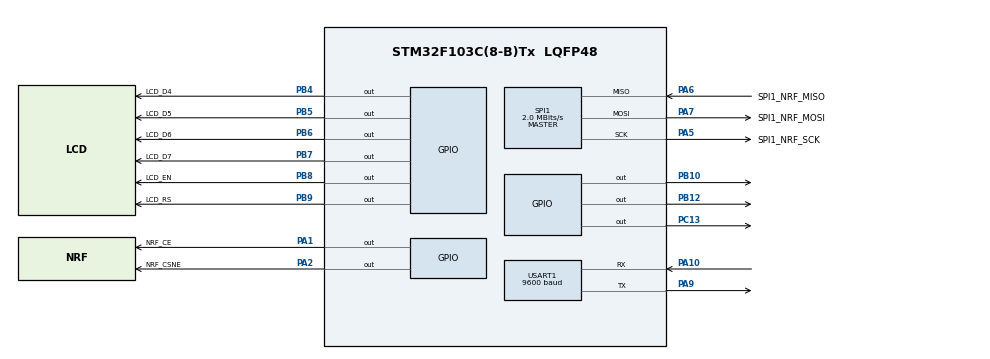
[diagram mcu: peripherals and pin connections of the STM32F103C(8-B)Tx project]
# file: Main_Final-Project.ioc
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Mcu.Family=STM32F1
Mcu.Name=STM32F103C(8-B)Tx
Mcu.Package=LQFP48
NVIC.PriorityGroup=NVIC_PRIORITYGROUP_4
PA1.GPIO_Label=NRF_CE
PA1.Signal=GPIO_Output
PA10.Mode=Asynchronous
PA10.Signal=USART1_RX
PA13.Mode=Serial_Wire
PA13.Signal=SYS_JTMS-SWDIO
PA14.Mode=Serial_Wire
PA14.Signal=SYS_JTCK-SWCLK
PA2.GPIO_Label=NRF_CSNE
PA2.Signal=GPIO_Output
PA5.GPIO_Label=SPI1_NRF_SCK
PA5.Mode=Full_Duplex_Master
PA5.Signal=SPI1_SCK
PA6.GPIO_Label=SPI1_NRF_MISO
PA6.Mode=Full_Duplex_Master
PA6.Signal=SPI1_MISO
PA7.GPIO_Label=SPI1_NRF_MOSI
PA7.Mode=Full_Duplex_Master
PA7.Signal=SPI1_MOSI
PA9.Mode=Asynchronous
PA9.Signal=USART1_TX
PB10.Signal=GPIO_Output
PB12.GPIO_Speed=GPIO_SPEED_FREQ_MEDIUM
PB12.PinState=GPIO_PIN_RESET
PB12.Signal=GPIO_Output
PB4.GPIO_Label=LCD_D4
PB4.Signal=GPIO_Output
PB5.GPIO_Label=LCD_D5
PB5.Signal=GPIO_Output
PB6.GPIO_Label=LCD_D6
PB6.Signal=GPIO_Output
PB7.GPIO_Label=LCD_D7
PB7.Signal=GPIO_Output
PB8.GPIO_Label=LCD_EN
PB8.Signal=GPIO_Output
PB9.GPIO_Label=LCD_RS
PB9.Signal=GPIO_Output
PC13-TAMPER-RTC.Signal=GPIO_Output
PD0-OSC_IN.Mode=HSE-External-Oscillator
PD0-OSC_IN.Signal=RCC_OSC_IN
PD1-OSC_OUT.Mode=HSE-External-Oscillator
PD1-OSC_OUT.Signal=RCC_OSC_OUT
ProjectManager.HeapSize=0x200
ProjectManager.StackSize=0x400
ProjectManager.TargetToolchain=STM32CubeIDE
RCC.AHBFreq_Value=8000000
RCC.APB1Freq_Value=8000000
RCC.APB1TimFreq_Value=8000000
RCC.APB2Freq_Value=8000000
RCC.APB2TimFreq_Value=8000000
RCC.HCLKFreq_Value=8000000
RCC.PLLSourceVirtual=RCC_PLLSOURCE_HSE
RCC.SYSCLKSource=RCC_SYSCLKSOURCE_HSE
RCC.TimSys_Div=SYSTICK_CLKSOURCE_HCLK_DIV8
RCC.USBFreq_Value=16000000
SPI1.BaudRatePrescaler=SPI_BAUDRATEPRESCALER_4
SPI1.CalculateBaudRate=2.0 MBits/s
SPI1.Direction=SPI_DIRECTION_2LINES
SPI1.Mode=SPI_MODE_MASTER
SPI1.VirtualType=VM_MASTER
USART1.BaudRate=9600
USART1.VirtualMode=VM_ASYNC
board=custom

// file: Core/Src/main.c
/* USER CODE BEGIN Header */
/**
  ******************************************************************************
  * @file           : main.c
  * @brief          : Main program body
  ******************************************************************************
  * @attention
  *
  * Copyright (c) 2023 STMicroelectronics.
  * All rights reserved.
  *
  * This software is licensed under terms that can be found in the LICENSE file
  * in the root directory of this software component.
  * If no LICENSE file comes with this software, it is provided AS-IS.
  *
  *Tx_NRF
  ******************************************************************************
  */
/* USER CODE END Header */
#include "main.h"

/* USER CODE BEGIN Includes */
#include "HAL/HAL_NRF.h"
/* USER CODE END Includes */

SPI_HandleTypeDef hspi1   ;
UART_HandleTypeDef huart1 ;

/* Data */

void SystemClock_Config(void);
static void MX_GPIO_Init(void);
static void MX_SPI1_Init(void);
static void MX_USART1_UART_Init(void);
void HAL_USART1_Send_Number(uint32_t Copy_u32Number) ;

/* USER CODE BEGIN 0 */

 /* Address of PIPE 1 */
uint8_t TxAddress[] = {0xEE,0xDD,0xCC,0xBB,0xAA} ;

/* Data to be Sent */
/*
 * S --> Speed
 * D --> Direction
 * M --> Distance
 * I --> Indication
 *
 */
/* SDMI */
uint8_t Data_States[5] = {'S','D','M','I'}  ;
uint8_t Data_Sent[10]  ;
uint8_t Debug_Var ;

/* USER CODE END 0 */

int main(void)
{

  /* MCU Configuration--------------------------------------------------------*/

  /* Reset of all peripherals, Initializes the Flash interface and the Systick. */
  HAL_Init();

  /* Configure the system clock */
  SystemClock_Config();

  /* Initialize all configured peripherals */

  MX_GPIO_Init();
  MX_SPI1_Init();
  MX_USART1_UART_Init();
  NRF_voidInit();
  NRF_voidTransmitterMode(TxAddress, 10 ) ;

  /* USER CODE BEGIN 2 */
  DataTransfer_t Data_Tx ;

  Data_Tx.Speed 	 = 25 						;  /* Input from MOTION Branch     */
  Data_Tx.Direction  = FORWARD 					;  /* Input from MOTION Branch     */
  Data_Tx.Distance 	 = 55 						;  /* Input from ULTRASONIC Branch */
  Data_Tx.Indication = INDICATION_SUDDEN_BREAK 	;

  /* USER CODE END 2 */

  /* Infinite loop */
  while (1)
  {

    /* USER CODE BEGIN 3 */

	  /* Speed Data */
	  Data_Sent[0] = Data_States[0] ;
	  Data_Sent[1] = Data_Tx.Speed  ;
	  NRF_voidSendData(Data_Sent,2,NRF_NUMBERS_EXIST) ;

	  /* Direction Data */
	  Data_Sent[0] = Data_States[1]     ;
	  Data_Sent[1] = Data_Tx.Direction  ;
	  NRF_voidSendData((Data_Sent),2,NRF_NUMBERS_EXIST)   ;

	  /* Distance Data */
	  Data_Sent[0] = Data_States[2]     ;
	  Data_Sent[1] = Data_Tx.Distance  ;
	  NRF_voidSendData((Data_Sent),2,NRF_NUMBERS_EXIST)   ;

	  /* Indication Data */
	  Data_Sent[0] = Data_States[3]      ;
	  Data_Sent[1] = Data_Tx.Indication  ;
	  NRF_voidSendData((Data_Sent),2,NRF_NUMBERS_EXIST)   ;

	  /**********************************************/

  }
  /* USER CODE END 3 */
}

void SystemClock_Config(void)
{
  RCC_OscInitTypeDef RCC_OscInitStruct = {0};
  RCC_ClkInitTypeDef RCC_ClkInitStruct = {0};

  /** Initializes the RCC Oscillators according to the specified parameters
  * in the RCC_OscInitTypeDef structure.
  */
  RCC_OscInitStruct.OscillatorType = RCC_OSCILLATORTYPE_HSE;
  RCC_OscInitStruct.HSEState = RCC_HSE_ON;
  RCC_OscInitStruct.PLL.PLLState = RCC_PLL_NONE;
  if (HAL_RCC_OscConfig(&RCC_OscInitStruct) != HAL_OK)
  {
    Error_Handler();
  }

  /** Initializes the CPU, AHB and APB buses clocks
  */
  RCC_ClkInitStruct.ClockType = RCC_CLOCKTYPE_HCLK|RCC_CLOCKTYPE_SYSCLK
                              |RCC_CLOCKTYPE_PCLK1|RCC_CLOCKTYPE_PCLK2;
  RCC_ClkInitStruct.SYSCLKSource = RCC_SYSCLKSOURCE_HSE;
  RCC_ClkInitStruct.AHBCLKDivider = RCC_SYSCLK_DIV1;
  RCC_ClkInitStruct.APB1CLKDivider = RCC_HCLK_DIV1;
  RCC_ClkInitStruct.APB2CLKDivider = RCC_HCLK_DIV1;

  if (HAL_RCC_ClockConfig(&RCC_ClkInitStruct, FLASH_LATENCY_0) != HAL_OK)
  {
    Error_Handler();
  }
}

static void MX_SPI1_Init(void)
{

  /* SPI1 parameter configuration*/
  hspi1.Instance = SPI1;
  hspi1.Init.Mode = SPI_MODE_MASTER;
  hspi1.Init.Direction = SPI_DIRECTION_2LINES;
  hspi1.Init.DataSize = SPI_DATASIZE_8BIT;
  hspi1.Init.CLKPolarity = SPI_POLARITY_LOW;
  hspi1.Init.CLKPhase = SPI_PHASE_1EDGE;
  hspi1.Init.NSS = SPI_NSS_SOFT;
  hspi1.Init.BaudRatePrescaler = SPI_BAUDRATEPRESCALER_4;
  hspi1.Init.FirstBit = SPI_FIRSTBIT_MSB;
  hspi1.Init.TIMode = SPI_TIMODE_DISABLE;
  hspi1.Init.CRCCalculation = SPI_CRCCALCULATION_DISABLE;
  hspi1.Init.CRCPolynomial = 10;
  if (HAL_SPI_Init(&hspi1) != HAL_OK)
  {
    Error_Handler();
  }

}

/**
  * @brief Send Numbers on UART
  * @param Number you want to print
  * @retval None
  */

 void HAL_USART1_Send_Number(uint32_t Copy_u32Number)
{
	uint8_t Local_u8Number_Element = 0  ;
	uint8_t Main_Arr[5] ;
	uint8_t Reverted_Arr[5] ;

    /* Reversing the digits */
    while (Copy_u32Number > 0)
    {
    	Main_Arr[Local_u8Number_Element] = (Copy_u32Number % 10) + 48 ;
    	Copy_u32Number = Copy_u32Number / 10 ;
    	Local_u8Number_Element++ ;
    }

    /* Copy the elements of Main_Arr --> Reverted_Arr then send them to UART in correct order */

    for (uint8_t Revert_Index = 0 ; Revert_Index<Local_u8Number_Element ; Revert_Index++)
    {
    	Reverted_Arr[Revert_Index] = Main_Arr[Local_u8Number_Element-Revert_Index-1] ;
    }

		HAL_UART_Transmit(&huart1, Reverted_Arr , Local_u8Number_Element, 100) ;

}

static void MX_USART1_UART_Init(void)
{

  huart1.Instance = USART1;
  huart1.Init.BaudRate = 9600;
  huart1.Init.WordLength = UART_WORDLENGTH_8B;
  huart1.Init.StopBits = UART_STOPBITS_1;
  huart1.Init.Parity = UART_PARITY_NONE;
  huart1.Init.Mode = UART_MODE_TX_RX;
  huart1.Init.HwFlowCtl = UART_HWCONTROL_NONE;
  huart1.Init.OverSampling = UART_OVERSAMPLING_16;
  if (HAL_UART_Init(&huart1) != HAL_OK)
  {
    Error_Handler();
  }

}

static void MX_GPIO_Init(void)
{
  GPIO_InitTypeDef GPIO_InitStruct = {0};

  /* GPIO Ports Clock Enable */
  __HAL_RCC_GPIOC_CLK_ENABLE();
  __HAL_RCC_GPIOD_CLK_ENABLE();
  __HAL_RCC_GPIOA_CLK_ENABLE();
  __HAL_RCC_GPIOB_CLK_ENABLE();

  /*Configure GPIO pin Output Level */
  HAL_GPIO_WritePin(Debug_LED_GPIO_Port, Debug_LED_Pin, GPIO_PIN_SET);

  /*Configure GPIO pin Output Level */
  HAL_GPIO_WritePin(GPIOA, NRF_CE_Pin|NRF_CSNE_Pin, GPIO_PIN_RESET);

  /*Configure GPIO pin Output Level */
  HAL_GPIO_WritePin(GPIOB, GPIO_PIN_10|GPIO_PIN_12|LCD_D4_Pin|LCD_D5_Pin
                          |LCD_D6_Pin|LCD_D7_Pin|LCD_EN_Pin|LCD_RS_Pin, GPIO_PIN_RESET);

  /*Configure GPIO pin : Debug_LED_Pin */
  GPIO_InitStruct.Pin = Debug_LED_Pin;
  GPIO_InitStruct.Mode = GPIO_MODE_OUTPUT_PP;
  GPIO_InitStruct.Pull = GPIO_NOPULL;
  GPIO_InitStruct.Speed = GPIO_SPEED_FREQ_LOW;
  HAL_GPIO_Init(Debug_LED_GPIO_Port, &GPIO_InitStruct);

  /*Configure GPIO pins : NRF_CE_Pin NRF_CSNE_Pin */
  GPIO_InitStruct.Pin = NRF_CE_Pin|NRF_CSNE_Pin;
  GPIO_InitStruct.Mode = GPIO_MODE_OUTPUT_PP;
  GPIO_InitStruct.Pull = GPIO_NOPULL;
  GPIO_InitStruct.Speed = GPIO_SPEED_FREQ_LOW;
  HAL_GPIO_Init(GPIOA, &GPIO_InitStruct);

  /*Configure GPIO pins : PB10 LCD_D4_Pin LCD_D5_Pin LCD_D6_Pin
                           LCD_D7_Pin LCD_EN_Pin LCD_RS_Pin */
  GPIO_InitStruct.Pin = GPIO_PIN_10|LCD_D4_Pin|LCD_D5_Pin|LCD_D6_Pin
                          |LCD_D7_Pin|LCD_EN_Pin|LCD_RS_Pin;
  GPIO_InitStruct.Mode = GPIO_MODE_OUTPUT_PP;
  GPIO_InitStruct.Pull = GPIO_NOPULL;
  GPIO_InitStruct.Speed = GPIO_SPEED_FREQ_LOW;
  HAL_GPIO_Init(GPIOB, &GPIO_InitStruct);

  /*Configure GPIO pin : PB12 */
  GPIO_InitStruct.Pin = GPIO_PIN_12;
  GPIO_InitStruct.Mode = GPIO_MODE_OUTPUT_PP;
  GPIO_InitStruct.Pull = GPIO_NOPULL;
  GPIO_InitStruct.Speed = GPIO_SPEED_FREQ_MEDIUM;
  HAL_GPIO_Init(GPIOB, &GPIO_InitStruct);

}

void Error_Handler(void)
{
  __disable_irq();
  while (1)
  {
  }
}
